# PIC32CX2051MTSH128S1 register map
Vendor: Microchip Technology; Series: PIC32CXMTSH; File version: 0
CPU: CM4 r0p1, selectable endian, MPU, FPU, 4 interrupt priority bits
Registers are 32-bit, read-write, reset 0x0 unless marked. A register's access mark holds for its fields unless they carry their own. Offsets are from the block's base; [hi:lo] are bit positions.

## QSPI — Quad Serial Peripheral Interface
Base 0x40020000; register names take the prefix QSPI_
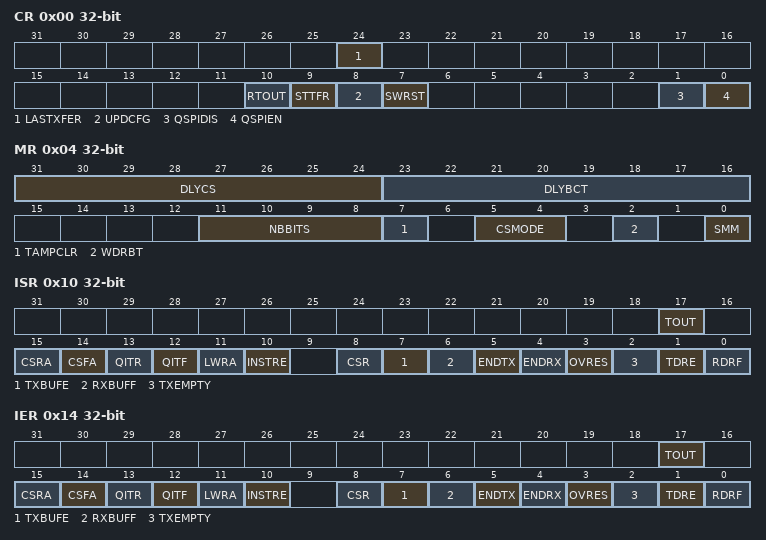
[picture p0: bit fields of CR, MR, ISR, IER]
0x00 CR wo — Control Register
  [24] LASTXFER — Last Transfer
  [10] RTOUT — Reset Time-out
  [9] STTFR — Start Transfer
  [8] UPDCFG — Update Configuration
  [7] SWRST — QSPI Software Reset
  [1] QSPIDIS — QSPI Disable
  [0] QSPIEN — QSPI Enable
0x04 MR — Mode Register
  [31:24] DLYCS — Minimum Inactive QCS Delay
  [23:16] DLYBCT — Delay Between Consecutive Transfers
  [11:8] NBBITS — Number Of Bits Per Transfer
    0=8_BIT (8 bits for transfer); 8=16_BIT (16 bits for transfer)
  [7] TAMPCLR — Tamper Clear Enable
  [5:4] CSMODE — Chip Select Mode
    0=NOT_RELOADED (The chip select is deasserted if QSPI_TDR.TD has not been reloaded before the end of the current transfer.); 1=LASTXFER (The chip select is deasserted when the bit LASTXFER is written to '1' and the character written in QSPI_TDR.TD has been transferred.); 2=SYSTEMATICALLY (The chip select is deasserted systematically after each transfer.)
  [2] WDRBT — Wait Data Read Before Transfer
    0=DISABLED (No effect. In SPI mode, a transfer can be initiated whatever the state of QSPI_RDR is.); 1=ENABLED (In SPI mode, a transfer can start only if QSPI_RDR is empty, i.e., does not contain any unread data. This mode prevents overrun error in reception.)
  [0] SMM — Serial Memory Mode
    0=SPI (The QSPI is in SPI mode.); 1=MEMORY (The QSPI is in Serial Memory mode.)
0x08 RDR ro — Receive Data Register
  [15:0] RD — Receive Data
0x0C TDR wo — Transmit Data Register
  [15:0] TD — Transmit Data
0x10 ISR ro — Interrupt Status Register
  [17] TOUT — QSPI Time-out
  [15] CSRA — Chip Select Rise Autoclear
  [14] CSFA — Chip Select Fall Autoclear
  [13] QITR — QSPI Interrupt Rise
  [12] QITF — QSPI Interrupt Fall
  [11] LWRA — Last Write Access (cleared on read)
  [10] INSTRE — Instruction End Status (cleared on read)
  [8] CSR — Chip Select Rise (cleared on read)
  [7] TXBUFE — TX Buffer Empty
  [6] RXBUFF — RX Buffer Full
  [5] ENDTX — End of TX buffer
  [4] ENDRX — End of RX buffer
  [3] OVRES — Overrun Error Status (cleared on read)
  [2] TXEMPTY — Transmission Registers Empty (cleared by writing QSPI_TDR)
  [1] TDRE — Transmit Data Register Empty (cleared by writing QSPI_TDR)
  [0] RDRF — Receive Data Register Full (cleared by reading QSPI_RDR)
0x14 IER wo — Interrupt Enable Register
  [17] TOUT — QSPI Time-out Interrupt Enable
  [15] CSRA — Chip Select Rise Autoclear Interrupt Enable
  [14] CSFA — Chip Select Fall Autoclear Interrupt Enable
  [13] QITR — QSPI Interrupt Rise Interrupt Enable
  [12] QITF — QSPI Interrupt Fall Interrupt Enable
  [11] LWRA — Last Write Access Interrupt Enable
  [10] INSTRE — Instruction End Interrupt Enable
  [8] CSR — Chip Select Rise Interrupt Enable
  [7] TXBUFE — Transmit Buffer Empty Interrupt Enable
  [6] RXBUFF — Receive Buffer Full Interrupt Enable
  [5] ENDTX — End of Transmit Buffer Interrupt Enable
  [4] ENDRX — End of Receive Buffer Interrupt Enable
  [3] OVRES — Overrun Error Interrupt Enable
  [2] TXEMPTY — Transmission Registers Empty Enable
  [1] TDRE — Transmit Data Register Empty Interrupt Enable
  [0] RDRF — Receive Data Register Full Interrupt Enable
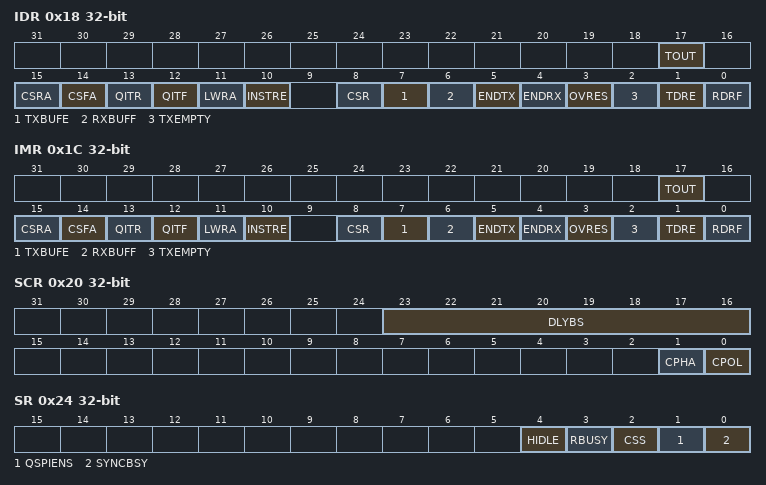
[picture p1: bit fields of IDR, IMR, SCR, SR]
0x18 IDR wo — Interrupt Disable Register
  [17] TOUT — QSPI Time-out Interrupt Disable
  [15] CSRA — Chip Select Rise Autoclear Interrupt Disable
  [14] CSFA — Chip Select Fall Autoclear Interrupt Disable
  [13] QITR — QSPI Interrupt Rise Interrupt Disable
  [12] QITF — QSPI Interrupt Fall Interrupt Disable
  [11] LWRA — Last Write Access Interrupt Disable
  [10] INSTRE — Instruction End Interrupt Disable
  [8] CSR — Chip Select Rise Interrupt Disable
  [7] TXBUFE — Transmit Buffer Empty Interrupt Disable
  [6] RXBUFF — Receive Buffer Full Interrupt Disable
  [5] ENDTX — End of Transmit Buffer Interrupt Disable
  [4] ENDRX — End of Receive Buffer Interrupt Disable
  [3] OVRES — Overrun Error Interrupt Disable
  [2] TXEMPTY — Transmission Registers Empty Disable
  [1] TDRE — Transmit Data Register Empty Interrupt Disable
  [0] RDRF — Receive Data Register Full Interrupt Disable
0x1C IMR ro — Interrupt Mask Register
  [17] TOUT — QSPI Time-out Interrupt Mask
  [15] CSRA — Chip Select Rise Autoclear Interrupt Mask
  [14] CSFA — Chip Select Fall Autoclear Interrupt Mask
  [13] QITR — QSPI Interrupt Rise Interrupt Mask
  [12] QITF — QSPI Interrupt Fall Interrupt Mask
  [11] LWRA — Last Write Access Interrupt Mask
  [10] INSTRE — Instruction End Interrupt Mask
  [8] CSR — Chip Select Rise Interrupt Mask
  [7] TXBUFE — Transmit Buffer Empty Interrupt Mask
  [6] RXBUFF — Receive Buffer Full Interrupt Mask
  [5] ENDTX — End of Transmit Buffer Interrupt Mask
  [4] ENDRX — End of Receive Buffer Interrupt Mask
  [3] OVRES — Overrun Error Interrupt Mask
  [2] TXEMPTY — Transmission Registers Empty Mask
  [1] TDRE — Transmit Data Register Empty Interrupt Mask
  [0] RDRF — Receive Data Register Full Interrupt Mask
0x20 SCR — Serial Clock Register
  [23:16] DLYBS — Delay Before QSCK
  [1] CPHA — Clock Phase
  [0] CPOL — Clock Polarity
0x24 SR — Status Register
  [4] HIDLE — QSPI Idle
  [3] RBUSY — Read Busy
  [2] CSS — Chip Select Status
  [1] QSPIENS — QSPI Enable Status
  [0] SYNCBSY — Synchronization Busy
0x30 IAR — Instruction Address Register
  [31:0] ADDR — Address
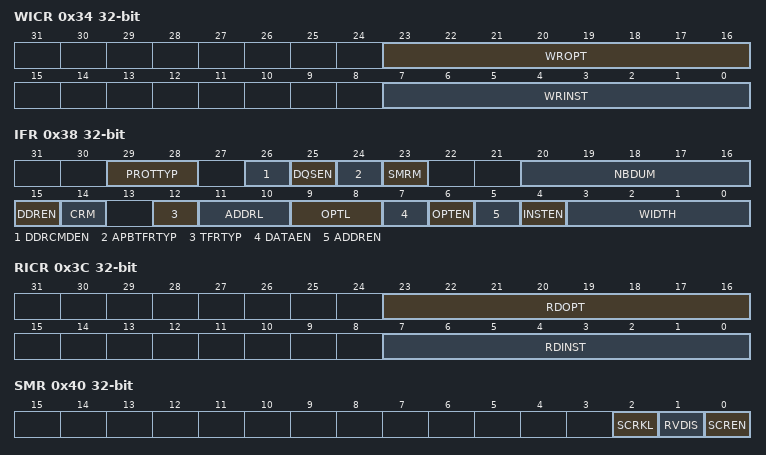
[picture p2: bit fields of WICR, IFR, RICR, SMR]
0x34 WICR — Write Instruction Code Register
  [23:16] WROPT — Write Option Code
  [7:0] WRINST — Write Instruction Code
0x38 IFR — Instruction Frame Register
  [29:28] PROTTYP — Protocol Type
    0=STD_SPI (Standard (Q)SPI Protocol)
  [26] DDRCMDEN — DDR Mode Command Enable
    0=DISABLED (Transfer of instruction field is performed in Single Data Rate mode even if DDREN is written to '1'.); 1=ENABLED (Transfer of instruction field is performed in Double Data Rate mode if DDREN bit is written to '1'. If DDREN is written to '0', the instruction field is sent in Single Data Rate mode.)
  [25] DQSEN — DQS Sampling Enable
  [24] APBTFRTYP — Peripheral BusTransfer Type
  [23] SMRM — Serial Memory Register Mode
  [20:16] NBDUM — Number Of Dummy Cycles
  [15] DDREN — DDR Mode Enable
    0=DISABLED (Transfers are performed in Single Data Rate mode.); 1=ENABLED (Transfers are performed in Double Data Rate mode, whereas the instruction field is still transferred in Single Data Rate mode.)
  [14] CRM — Continuous Read Mode
    0=DISABLED (Continuous Read mode is disabled.); 1=ENABLED (Continuous Read mode is enabled.)
  [12] TFRTYP — Data Transfer Type
    0=TRSFR_REGISTER (Read/Write of memory register, write of memory page buffer. This configuration implies the following: Either the AHB or the APB interface can be used to initiate the transfer (SMRM bit). Returned data represents the memory register value. If the APB interface is used, the RDRF and TDRE flags help to control the frame. Scrambling is possible only if the APB interface is used. For HyperFlash memories the 'target' bit is set to register space in the HyperFlash header.); 1=TRSFR_MEMORY (Read/Write accesses to the memory space. This configuration implies the following: Only the System Bus interface can be used to trigger accesses. Access to random location is possible. Address mask is applied and full size accesses only are performed. Internal optimization algorithm is enabled to minimize latency. Data are returned in a system bus protocol compliant way. Seamless scrambling is enabled. Seamless handling of HyperFlash Write Buffer programming command (one command for each data) Seamless protocol-specific page boundary handling Address shift is handled seamlessly (e.g. halfword memories).)
  [11:10] ADDRL — Address Length
    0=_8_BIT (8-bit address size); 1=_16_BIT (16-bit address size); 2=_24_BIT (24-bit address size); 3=_32_BIT (32-bit address size)
  [9:8] OPTL — Option Code Length
    0=OPTION_1BIT (The option code is 1 bit long.); 1=OPTION_2BIT (The option code is 2 bits long.); 2=OPTION_4BIT (The option code is 4 bits long.); 3=OPTION_8BIT (The option code is 8 bits long.)
  [7] DATAEN — Data Enable
  [6] OPTEN — Option Enable
  [5] ADDREN — Address Enable
  [4] INSTEN — Instruction Enable
  [3:0] WIDTH — Width of Instruction Code, Address, Option Code and Data
    0=SINGLE_BIT_SPI (Instruction: Single-bit SPI / Address-Option: Single-bit SPI / Data: Single-bit SPI); 1=DUAL_OUTPUT (Instruction: Single-bit SPI / Address-Option: Single-bit SPI / Data: Dual SPI); 2=QUAD_OUTPUT (Instruction: Single-bit SPI / Address-Option: Single-bit SPI / Data: Quad SPI); 3=DUAL_IO (Instruction: Single-bit SPI / Address-Option: Dual SPI / Data: Dual SPI); 4=QUAD_IO (Instruction: Single-bit SPI / Address-Option: Quad SPI / Data: Quad SPI); 5=DUAL_CMD (Instruction: Dual SPI / Address-Option: Dual SPI / Data: Dual SPI); 6=QUAD_CMD (Instruction: Quad SPI / Address-Option: Quad SPI / Data: Quad SPI)
0x3C RICR — Read Instruction Code Register
  [23:16] RDOPT — Read Option Code
  [7:0] RDINST — Read Instruction Code
0x40 SMR — Scrambling Mode Register
  [2] SCRKL — Scrambling Key Lock
  [1] RVDIS — Scrambling/Unscrambling Random Value Disable
  [0] SCREN — Scrambling/Unscrambling Enable
    0=DISABLED (The scrambling/unscrambling is disabled.); 1=ENABLED (The scrambling/unscrambling is enabled.)
0x44 SKR wo — Scrambling Key Register
  [31:0] USRK — User Scrambling Key
0x54 WRACNT — Write Access Counter Register
  [31:0] NBWRA — Number of Write Accesses
0x64 TOUT — Timeout Register
  [15:0] TCNTM — Time-out Counter Maximum Value
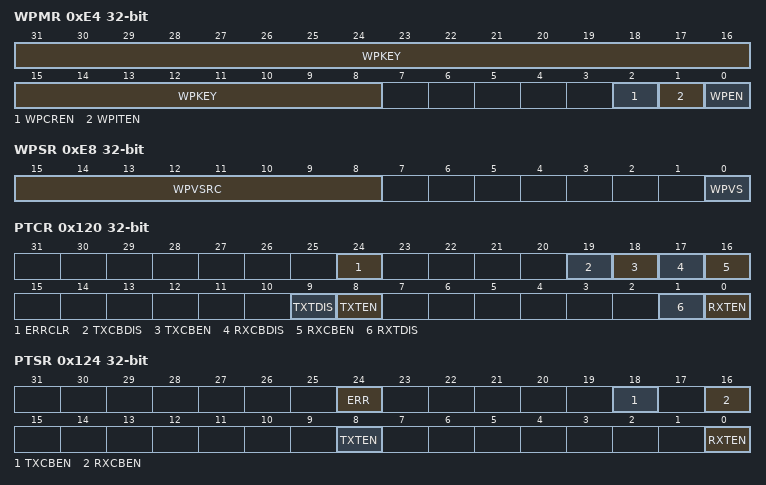
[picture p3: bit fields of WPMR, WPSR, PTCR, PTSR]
0xE4 WPMR — Write Protection Mode Register
  [31:8] WPKEY — Write Protection Key
    0x515350=PASSWD (Writing any other value in this field aborts the write operation of the WPEN bit. Always reads as 0.)
  [2] WPCREN — Write Protection Control Register Enable
  [1] WPITEN — Write Protection Interrupt Enable
  [0] WPEN — Write Protection Enable
0xE8 WPSR ro — Write Protection Status Register
  [15:8] WPVSRC — Write Protection Violation Source
  [0] WPVS — Write Protection Violation Status
0x100 RPR — Receive Pointer Register
  [31:0] RXPTR
0x104 RCR — Receive Counter Register
  [15:0] RXCTR
0x108 TPR — Transmit Pointer Register
  [31:0] TXPTR — Transmit Counter Register
0x10C TCR — Transmit Counter Register
  [15:0] TXCTR
0x110 RNPR — Receive Next Pointer Register
  [31:0] RXNPTR — Receive Next Pointer
0x114 RNCR — Receive Next Counter Register
  [15:0] RXNCTR — Receive Next Counter
0x118 TNPR — Transmit Next Pointer Register
  [31:0] TXNPTR — Transmit Next Pointer
0x11C TNCR — Transmit Next Counter Register
  [15:0] TXNCTR — Transmit Counter Next
0x120 PTCR wo — Transfer Control Register
  [24] ERRCLR — Transfer Bus Error Clear
  [19] TXCBDIS — Transmitter Circular Buffer Disable
  [18] TXCBEN — Transmitter Circular Buffer Enable
  [17] RXCBDIS — Receiver Circular Buffer Disable
  [16] RXCBEN — Receiver Circular Buffer Enable
  [9] TXTDIS — Transmitter Transfer Disable
  [8] TXTEN — Transmitter Transfer Enable
  [1] RXTDIS — Receiver Transfer Disable
  [0] RXTEN — Receiver Transfer Enable
0x124 PTSR ro — Transfer Status Register
  [24] ERR — Transfer Bus Error
  [18] TXCBEN — Transmitter Circular Buffer Enable
  [16] RXCBEN — Receiver Circular Buffer Enable
  [8] TXTEN — Transmitter Transfer Enable
  [0] RXTEN — Receiver Transfer Enable
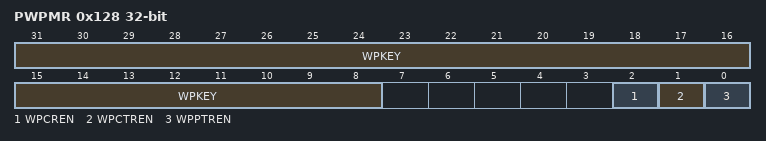
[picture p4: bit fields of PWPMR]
0x128 PWPMR — Write Protection Mode Register
  [31:8] WPKEY — Write Protection Key
    0x504443=PASSWD (Writing any other value in this field aborts the write operation. Always reads as 0.)
  [2] WPCREN — Write Protection Control Register Enable
  [1] WPCTREN — Write Protection Counter Registers Enable
  [0] WPPTREN — Write Protection Pointer Registers Enable

## Notices in the file
Copyright (c) 2017 Microchip Technology Inc.
SPDX-License-Identifier: Apache-2.0
Licensed under the Apache License, Version 2.0 (the "License");
you may not use this file except in compliance with the License.
You may obtain a copy of the License at
http://www.apache.org/licenses/LICENSE-2.0
Unless required by applicable law or agreed to in writing, software
distributed under the License is distributed on an "AS IS" BASIS,
WITHOUT WARRANTIES OR CONDITIONS OF ANY KIND, either express or implied.
See the License for the specific language governing permissions and
limitations under the License.
